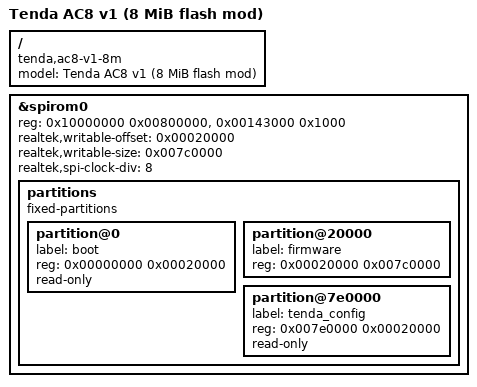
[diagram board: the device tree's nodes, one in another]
// SPDX-License-Identifier: GPL-2.0-or-later OR MIT
/*
 * Tenda AC8 v1 with 8 MiB (replaced chip, e.g. W25Q64) SPI-NOR flash.
 *
 *   0x000000..0x020000  Realtek boot loader + Tenda board data at 0x1c000
 *   0x020000..0x7e0000  firmware: cs6c header + loader/kernel + SquashFS
 *   0x7e0000..0x800000  Tenda config block (read-only, unverified)
 */

#include "rtl8197f_tenda_ac8-v1.dtsi"

/ {
	compatible = "tenda,ac8-v1-8m", "tenda,ac8-v1", "realtek,rtl8197f-vg", "realtek,rtl8197f-soc";
	model = "Tenda AC8 v1 (8 MiB flash mod)";
};

&spirom0 {
	reg = <0x10000000 0x00800000>, <0x00143000 0x1000>;

	/*
	 * Program/erase are accepted only inside the firmware partition:
	 * sysupgrade rewrites it and the JFFS2 overlay lives in its
	 * rootfs_data tail, while the boot loader with the board data and
	 * the last 128 KiB stay out of reach of the driver.
	 */
	realtek,writable-offset = <0x00020000>;
	realtek,writable-size = <0x007c0000>;
	realtek,spi-clock-div = <8>;

	partitions {
		compatible = "fixed-partitions";
		#address-cells = <1>;
		#size-cells = <1>;

		partition@0 {
			label = "boot";
			reg = <0x00000000 0x00020000>;
			read-only;
		};

		/*
		 * No compatible here: the rtl8197f-fw mtdsplit parser is selected
		 * by the partition name and splits kernel/rootfs from the cs6c
		 * header length.
		 */
		partition@20000 {
			label = "firmware";
			reg = <0x00020000 0x007c0000>;
		};

		partition@7e0000 {
			label = "tenda_config";
			reg = <0x007e0000 0x00020000>;
			read-only;
		};
	};
};
